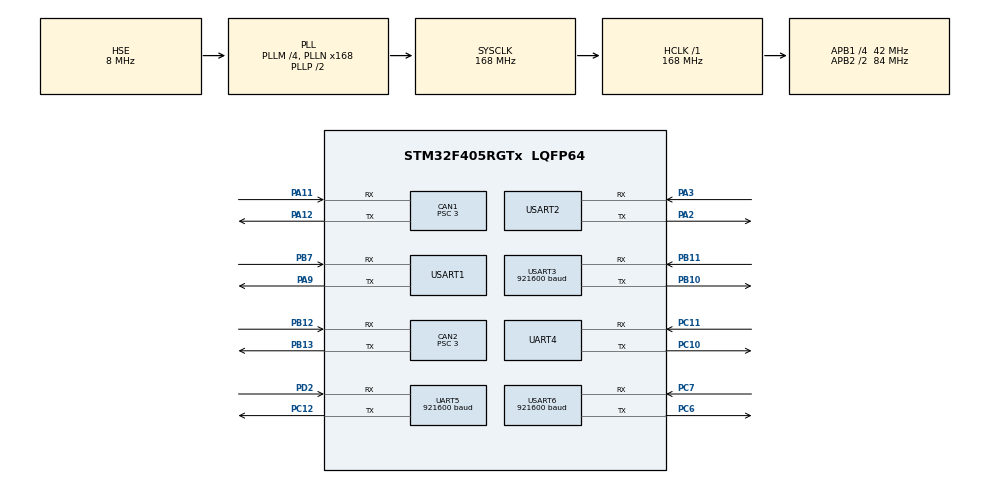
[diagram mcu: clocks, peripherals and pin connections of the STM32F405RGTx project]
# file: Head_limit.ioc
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CAN1.ABOM=ENABLE
CAN1.BS1=CAN_BS1_10TQ
CAN1.BS2=CAN_BS2_3TQ
CAN1.CalculateBaudRate=1000000
CAN1.CalculateTimeBit=1000
CAN1.CalculateTimeQuantum=71.42857142857143
CAN1.NART=ENABLE
CAN1.Prescaler=3
CAN2.ABOM=ENABLE
CAN2.BS1=CAN_BS1_10TQ
CAN2.BS2=CAN_BS2_3TQ
CAN2.CalculateBaudRate=1000000
CAN2.CalculateTimeBit=1000
CAN2.CalculateTimeQuantum=71.42857142857143
CAN2.NART=ENABLE
CAN2.Prescaler=3
Dma.Request0=USART2_RX
Dma.Request1=USART2_TX
Dma.Request2=USART3_RX
Dma.Request3=USART6_RX
Dma.Request4=UART5_RX
Dma.Request5=USART3_TX
Dma.UART5_RX.4.Direction=DMA_PERIPH_TO_MEMORY
Dma.UART5_RX.4.FIFOMode=DMA_FIFOMODE_DISABLE
Dma.UART5_RX.4.Instance=DMA1_Stream0
Dma.UART5_RX.4.MemDataAlignment=DMA_MDATAALIGN_BYTE
Dma.UART5_RX.4.MemInc=DMA_MINC_ENABLE
Dma.UART5_RX.4.Mode=DMA_CIRCULAR
Dma.UART5_RX.4.PeriphDataAlignment=DMA_PDATAALIGN_BYTE
Dma.UART5_RX.4.PeriphInc=DMA_PINC_DISABLE
Dma.UART5_RX.4.Priority=DMA_PRIORITY_LOW
Dma.USART2_RX.0.Direction=DMA_PERIPH_TO_MEMORY
Dma.USART2_RX.0.FIFOMode=DMA_FIFOMODE_DISABLE
Dma.USART2_RX.0.Instance=DMA1_Stream5
Dma.USART2_RX.0.MemDataAlignment=DMA_MDATAALIGN_BYTE
Dma.USART2_RX.0.MemInc=DMA_MINC_ENABLE
Dma.USART2_RX.0.Mode=DMA_CIRCULAR
Dma.USART2_RX.0.PeriphDataAlignment=DMA_PDATAALIGN_BYTE
Dma.USART2_RX.0.PeriphInc=DMA_PINC_DISABLE
Dma.USART2_RX.0.Priority=DMA_PRIORITY_LOW
Dma.USART2_TX.1.Direction=DMA_MEMORY_TO_PERIPH
Dma.USART2_TX.1.FIFOMode=DMA_FIFOMODE_DISABLE
Dma.USART2_TX.1.Instance=DMA1_Stream6
Dma.USART2_TX.1.MemDataAlignment=DMA_MDATAALIGN_BYTE
Dma.USART2_TX.1.MemInc=DMA_MINC_ENABLE
Dma.USART2_TX.1.Mode=DMA_CIRCULAR
Dma.USART2_TX.1.PeriphDataAlignment=DMA_PDATAALIGN_BYTE
Dma.USART2_TX.1.PeriphInc=DMA_PINC_DISABLE
Dma.USART2_TX.1.Priority=DMA_PRIORITY_LOW
Dma.USART3_RX.2.Direction=DMA_PERIPH_TO_MEMORY
Dma.USART3_RX.2.FIFOMode=DMA_FIFOMODE_DISABLE
Dma.USART3_RX.2.Instance=DMA1_Stream1
Dma.USART3_RX.2.MemDataAlignment=DMA_MDATAALIGN_BYTE
Dma.USART3_RX.2.MemInc=DMA_MINC_ENABLE
Dma.USART3_RX.2.Mode=DMA_CIRCULAR
Dma.USART3_RX.2.PeriphDataAlignment=DMA_PDATAALIGN_BYTE
Dma.USART3_RX.2.PeriphInc=DMA_PINC_DISABLE
Dma.USART3_RX.2.Priority=DMA_PRIORITY_LOW
Dma.USART3_TX.5.Direction=DMA_MEMORY_TO_PERIPH
Dma.USART3_TX.5.FIFOMode=DMA_FIFOMODE_DISABLE
Dma.USART3_TX.5.Instance=DMA1_Stream3
Dma.USART3_TX.5.MemDataAlignment=DMA_MDATAALIGN_BYTE
Dma.USART3_TX.5.MemInc=DMA_MINC_ENABLE
Dma.USART3_TX.5.Mode=DMA_NORMAL
Dma.USART3_TX.5.PeriphDataAlignment=DMA_PDATAALIGN_BYTE
Dma.USART3_TX.5.PeriphInc=DMA_PINC_DISABLE
Dma.USART3_TX.5.Priority=DMA_PRIORITY_LOW
Dma.USART6_RX.3.Direction=DMA_PERIPH_TO_MEMORY
Dma.USART6_RX.3.FIFOMode=DMA_FIFOMODE_DISABLE
Dma.USART6_RX.3.Instance=DMA2_Stream1
Dma.USART6_RX.3.MemDataAlignment=DMA_MDATAALIGN_BYTE
Dma.USART6_RX.3.MemInc=DMA_MINC_ENABLE
Dma.USART6_RX.3.Mode=DMA_CIRCULAR
Dma.USART6_RX.3.PeriphDataAlignment=DMA_PDATAALIGN_BYTE
Dma.USART6_RX.3.PeriphInc=DMA_PINC_DISABLE
Dma.USART6_RX.3.Priority=DMA_PRIORITY_LOW
Mcu.Family=STM32F4
Mcu.Name=STM32F405RGTx
Mcu.Package=LQFP64
NVIC.CAN1_RX0_IRQn=true\:0\:0\:false\:false\:true\:true\:true\:true
NVIC.CAN2_RX0_IRQn=true\:0\:0\:false\:false\:true\:true\:true\:true
NVIC.DMA1_Stream0_IRQn=true\:0\:0\:false\:false\:true\:false\:true\:true
NVIC.DMA1_Stream1_IRQn=true\:0\:0\:false\:false\:true\:false\:true\:true
NVIC.DMA1_Stream3_IRQn=true\:0\:0\:false\:false\:true\:false\:true\:true
NVIC.DMA1_Stream5_IRQn=true\:0\:0\:false\:false\:true\:false\:true\:true
NVIC.DMA1_Stream6_IRQn=true\:0\:0\:false\:false\:true\:false\:true\:true
NVIC.DMA2_Stream1_IRQn=true\:0\:0\:false\:false\:true\:false\:true\:true
NVIC.PriorityGroup=NVIC_PRIORITYGROUP_4
NVIC.TIM6_DAC_IRQn=true\:0\:0\:false\:false\:true\:true\:true\:true
NVIC.UART4_IRQn=true\:0\:0\:false\:false\:true\:true\:true\:true
NVIC.UART5_IRQn=true\:0\:0\:false\:false\:true\:true\:true\:true
NVIC.USART1_IRQn=true\:0\:0\:false\:false\:true\:true\:true\:true
NVIC.USART2_IRQn=true\:0\:0\:false\:false\:true\:true\:true\:true
NVIC.USART3_IRQn=true\:0\:0\:false\:false\:true\:true\:true\:true
NVIC.USART6_IRQn=true\:0\:0\:false\:false\:true\:true\:true\:true
PA11.Mode=CAN_Activate
PA11.Signal=CAN1_RX
PA12.Mode=CAN_Activate
PA12.Signal=CAN1_TX
PA13.Mode=Serial_Wire
PA13.Signal=SYS_JTMS-SWDIO
PA14.Mode=Serial_Wire
PA14.Signal=SYS_JTCK-SWCLK
PA2.Mode=Asynchronous
PA2.Signal=USART2_TX
PA3.GPIO_PuPd=GPIO_NOPULL
PA3.Mode=Asynchronous
PA3.Signal=USART2_RX
PA9.Mode=Asynchronous
PA9.Signal=USART1_TX
PB10.Mode=Asynchronous
PB10.Signal=USART3_TX
PB11.GPIO_PuPd=GPIO_PULLUP
PB11.GPIO_Speed=GPIO_SPEED_FREQ_HIGH
PB11.Mode=Asynchronous
PB11.Signal=USART3_RX
PB12.Mode=CAN_Activate
PB12.Signal=CAN2_RX
PB13.Mode=CAN_Activate
PB13.Signal=CAN2_TX
PB7.Mode=Asynchronous
PB7.Signal=USART1_RX
PC10.Mode=Asynchronous
PC10.Signal=UART4_TX
PC11.Mode=Asynchronous
PC11.Signal=UART4_RX
PC12.Mode=Asynchronous
PC12.Signal=UART5_TX
PC6.GPIO_Speed=GPIO_SPEED_FREQ_HIGH
PC6.Mode=Asynchronous
PC6.Signal=USART6_TX
PC7.Mode=Asynchronous
PC7.Signal=USART6_RX
PD2.Mode=Asynchronous
PD2.Signal=UART5_RX
PH0-OSC_IN.Mode=HSE-External-Oscillator
PH0-OSC_IN.Signal=RCC_OSC_IN
PH1-OSC_OUT.Mode=HSE-External-Oscillator
PH1-OSC_OUT.Signal=RCC_OSC_OUT
ProjectManager.HeapSize=0x200
ProjectManager.StackSize=0x400
ProjectManager.TargetToolchain=MDK-ARM V5.32
RCC.48MHZClocksFreq_Value=84000000
RCC.AHBFreq_Value=168000000
RCC.APB1CLKDivider=RCC_HCLK_DIV4
RCC.APB1Freq_Value=42000000
RCC.APB1TimFreq_Value=84000000
RCC.APB2CLKDivider=RCC_HCLK_DIV2
RCC.APB2Freq_Value=84000000
RCC.APB2TimFreq_Value=168000000
RCC.CortexFreq_Value=168000000
RCC.HCLKFreq_Value=168000000
RCC.HSE_VALUE=8000000
RCC.HSI_VALUE=16000000
RCC.LSE_VALUE=32768
RCC.PLLM=4
RCC.PLLN=168
RCC.PLLSourceVirtual=RCC_PLLSOURCE_HSE
RCC.SYSCLKFreq_VALUE=168000000
RCC.SYSCLKSource=RCC_SYSCLKSOURCE_PLLCLK
RCC.VCOOutputFreq_Value=336000000
TIM6.Period=999
TIM6.Prescaler=83
UART4.VirtualMode=Asynchronous
UART5.BaudRate=921600
UART5.VirtualMode=Asynchronous
USART1.VirtualMode=VM_ASYNC
USART2.VirtualMode=VM_ASYNC
USART3.BaudRate=921600
USART3.VirtualMode=VM_ASYNC
USART6.BaudRate=921600
USART6.VirtualMode=VM_ASYNC
VP_TIM6_VS_ClockSourceINT.Mode=Enable_Timer
board=custom

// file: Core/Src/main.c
/* USER CODE BEGIN Header */
/**
  ******************************************************************************
  * @file           : main.c
  * @brief          : Main program body
  ******************************************************************************
  * @attention
  *
  * Copyright (c) 2026 STMicroelectronics.
  * All rights reserved.
  *
  * This software is licensed under terms that can be found in the LICENSE file
  * in the root directory of this software component.
  * If no LICENSE file comes with this software, it is provided AS-IS.
  *
  ******************************************************************************
  */
/* USER CODE END Header */
#include "main.h"

/* USER CODE BEGIN Includes */
#include "BSP.h"
#include "Shoot_Task.h"
#include "Up_Task.h"

/* USER CODE END Includes */

CAN_HandleTypeDef hcan1;
CAN_HandleTypeDef hcan2;

TIM_HandleTypeDef htim6;

UART_HandleTypeDef huart4;
UART_HandleTypeDef huart5;
UART_HandleTypeDef huart1;
UART_HandleTypeDef huart2;
UART_HandleTypeDef huart3;
UART_HandleTypeDef huart6;
DMA_HandleTypeDef hdma_uart5_rx;
DMA_HandleTypeDef hdma_usart2_rx;
DMA_HandleTypeDef hdma_usart2_tx;
DMA_HandleTypeDef hdma_usart3_rx;
DMA_HandleTypeDef hdma_usart3_tx;
DMA_HandleTypeDef hdma_usart6_rx;

void SystemClock_Config(void);
static void MX_GPIO_Init(void);
static void MX_DMA_Init(void);
static void MX_CAN1_Init(void);
static void MX_CAN2_Init(void);
static void MX_UART4_Init(void);
static void MX_UART5_Init(void);
static void MX_USART1_UART_Init(void);
static void MX_USART2_UART_Init(void);
static void MX_USART3_UART_Init(void);
static void MX_USART6_UART_Init(void);
static void MX_TIM6_Init(void);

int main(void)
{

  /* MCU Configuration--------------------------------------------------------*/

  /* Reset of all peripherals, Initializes the Flash interface and the Systick. */
  HAL_Init();

  /* Configure the system clock */
  SystemClock_Config();

  /* Initialize all configured peripherals */
  MX_GPIO_Init();
  MX_DMA_Init();
  MX_CAN1_Init();
  MX_CAN2_Init();
  MX_UART4_Init();
  MX_UART5_Init();
  MX_USART1_UART_Init();
  MX_USART2_UART_Init();
  MX_USART3_UART_Init();
  MX_USART6_UART_Init();
  MX_TIM6_Init();
  /* USER CODE BEGIN 2 */
  /* 启动 BSP 侧的软件初始化，包括串口 DMA、CAN 和 1 kHz 定时器任务。 */
  BSP_Init();
  /* 初始化控制任务状态。 */
  Up_Task_Init();
  Shoot_Task_Init();

  /* USER CODE END 2 */

  /* Infinite loop */
  while (1)
  {

    /* USER CODE BEGIN 3 */
    /* 主循环持续消费串口环形缓冲，并分发给遥控/IMU 模块解析。 */
    BSP_Poll();
  }
  /* USER CODE END 3 */
}

void SystemClock_Config(void)
{
  RCC_OscInitTypeDef RCC_OscInitStruct = {0};
  RCC_ClkInitTypeDef RCC_ClkInitStruct = {0};

  /** Configure the main internal regulator output voltage
  */
  __HAL_RCC_PWR_CLK_ENABLE();
  __HAL_PWR_VOLTAGESCALING_CONFIG(PWR_REGULATOR_VOLTAGE_SCALE1);

  /** Initializes the RCC Oscillators according to the specified parameters
  * in the RCC_OscInitTypeDef structure.
  */
  RCC_OscInitStruct.OscillatorType = RCC_OSCILLATORTYPE_HSE;
  RCC_OscInitStruct.HSEState = RCC_HSE_ON;
  RCC_OscInitStruct.PLL.PLLState = RCC_PLL_ON;
  RCC_OscInitStruct.PLL.PLLSource = RCC_PLLSOURCE_HSE;
  RCC_OscInitStruct.PLL.PLLM = 4;
  RCC_OscInitStruct.PLL.PLLN = 168;
  RCC_OscInitStruct.PLL.PLLP = RCC_PLLP_DIV2;
  RCC_OscInitStruct.PLL.PLLQ = 4;
  if (HAL_RCC_OscConfig(&RCC_OscInitStruct) != HAL_OK)
  {
    Error_Handler();
  }

  /** Initializes the CPU, AHB and APB buses clocks
  */
  RCC_ClkInitStruct.ClockType = RCC_CLOCKTYPE_HCLK|RCC_CLOCKTYPE_SYSCLK
                              |RCC_CLOCKTYPE_PCLK1|RCC_CLOCKTYPE_PCLK2;
  RCC_ClkInitStruct.SYSCLKSource = RCC_SYSCLKSOURCE_PLLCLK;
  RCC_ClkInitStruct.AHBCLKDivider = RCC_SYSCLK_DIV1;
  RCC_ClkInitStruct.APB1CLKDivider = RCC_HCLK_DIV4;
  RCC_ClkInitStruct.APB2CLKDivider = RCC_HCLK_DIV2;

  if (HAL_RCC_ClockConfig(&RCC_ClkInitStruct, FLASH_LATENCY_5) != HAL_OK)
  {
    Error_Handler();
  }
}

static void MX_CAN1_Init(void)
{

  hcan1.Instance = CAN1;
  hcan1.Init.Prescaler = 3;
  hcan1.Init.Mode = CAN_MODE_NORMAL;
  hcan1.Init.SyncJumpWidth = CAN_SJW_1TQ;
  hcan1.Init.TimeSeg1 = CAN_BS1_10TQ;
  hcan1.Init.TimeSeg2 = CAN_BS2_3TQ;
  hcan1.Init.TimeTriggeredMode = DISABLE;
  hcan1.Init.AutoBusOff = ENABLE;
  hcan1.Init.AutoWakeUp = DISABLE;
  hcan1.Init.AutoRetransmission = ENABLE;
  hcan1.Init.ReceiveFifoLocked = DISABLE;
  hcan1.Init.TransmitFifoPriority = DISABLE;
  if (HAL_CAN_Init(&hcan1) != HAL_OK)
  {
    Error_Handler();
  }

}

static void MX_CAN2_Init(void)
{

  hcan2.Instance = CAN2;
  hcan2.Init.Prescaler = 3;
  hcan2.Init.Mode = CAN_MODE_NORMAL;
  hcan2.Init.SyncJumpWidth = CAN_SJW_1TQ;
  hcan2.Init.TimeSeg1 = CAN_BS1_10TQ;
  hcan2.Init.TimeSeg2 = CAN_BS2_3TQ;
  hcan2.Init.TimeTriggeredMode = DISABLE;
  hcan2.Init.AutoBusOff = ENABLE;
  hcan2.Init.AutoWakeUp = DISABLE;
  hcan2.Init.AutoRetransmission = ENABLE;
  hcan2.Init.ReceiveFifoLocked = DISABLE;
  hcan2.Init.TransmitFifoPriority = DISABLE;
  if (HAL_CAN_Init(&hcan2) != HAL_OK)
  {
    Error_Handler();
  }

}

static void MX_TIM6_Init(void)
{

  TIM_MasterConfigTypeDef sMasterConfig = {0};

  htim6.Instance = TIM6;
  htim6.Init.Prescaler = 83;
  htim6.Init.CounterMode = TIM_COUNTERMODE_UP;
  htim6.Init.Period = 999;
  htim6.Init.AutoReloadPreload = TIM_AUTORELOAD_PRELOAD_DISABLE;
  if (HAL_TIM_Base_Init(&htim6) != HAL_OK)
  {
    Error_Handler();
  }
  sMasterConfig.MasterOutputTrigger = TIM_TRGO_RESET;
  sMasterConfig.MasterSlaveMode = TIM_MASTERSLAVEMODE_DISABLE;
  if (HAL_TIMEx_MasterConfigSynchronization(&htim6, &sMasterConfig) != HAL_OK)
  {
    Error_Handler();
  }

}

static void MX_UART4_Init(void)
{

  huart4.Instance = UART4;
  huart4.Init.BaudRate = 115200;
  huart4.Init.WordLength = UART_WORDLENGTH_8B;
  huart4.Init.StopBits = UART_STOPBITS_1;
  huart4.Init.Parity = UART_PARITY_NONE;
  huart4.Init.Mode = UART_MODE_TX_RX;
  huart4.Init.HwFlowCtl = UART_HWCONTROL_NONE;
  huart4.Init.OverSampling = UART_OVERSAMPLING_16;
  if (HAL_UART_Init(&huart4) != HAL_OK)
  {
    Error_Handler();
  }

}

static void MX_UART5_Init(void)
{

  huart5.Instance = UART5;
  huart5.Init.BaudRate = 921600;
  huart5.Init.WordLength = UART_WORDLENGTH_8B;
  huart5.Init.StopBits = UART_STOPBITS_1;
  huart5.Init.Parity = UART_PARITY_NONE;
  huart5.Init.Mode = UART_MODE_TX_RX;
  huart5.Init.HwFlowCtl = UART_HWCONTROL_NONE;
  huart5.Init.OverSampling = UART_OVERSAMPLING_16;
  if (HAL_UART_Init(&huart5) != HAL_OK)
  {
    Error_Handler();
  }

}

static void MX_USART1_UART_Init(void)
{

  huart1.Instance = USART1;
  huart1.Init.BaudRate = 115200;
  huart1.Init.WordLength = UART_WORDLENGTH_8B;
  huart1.Init.StopBits = UART_STOPBITS_1;
  huart1.Init.Parity = UART_PARITY_NONE;
  huart1.Init.Mode = UART_MODE_TX_RX;
  huart1.Init.HwFlowCtl = UART_HWCONTROL_NONE;
  huart1.Init.OverSampling = UART_OVERSAMPLING_16;
  if (HAL_UART_Init(&huart1) != HAL_OK)
  {
    Error_Handler();
  }

}

static void MX_USART2_UART_Init(void)
{

  huart2.Instance = USART2;
  huart2.Init.BaudRate = 115200;
  huart2.Init.WordLength = UART_WORDLENGTH_8B;
  huart2.Init.StopBits = UART_STOPBITS_1;
  huart2.Init.Parity = UART_PARITY_NONE;
  huart2.Init.Mode = UART_MODE_TX_RX;
  huart2.Init.HwFlowCtl = UART_HWCONTROL_NONE;
  huart2.Init.OverSampling = UART_OVERSAMPLING_16;
  if (HAL_UART_Init(&huart2) != HAL_OK)
  {
    Error_Handler();
  }

}

static void MX_USART3_UART_Init(void)
{

  huart3.Instance = USART3;
  huart3.Init.BaudRate = 921600;
  huart3.Init.WordLength = UART_WORDLENGTH_8B;
  huart3.Init.StopBits = UART_STOPBITS_1;
  huart3.Init.Parity = UART_PARITY_NONE;
  huart3.Init.Mode = UART_MODE_TX_RX;
  huart3.Init.HwFlowCtl = UART_HWCONTROL_NONE;
  huart3.Init.OverSampling = UART_OVERSAMPLING_16;
  if (HAL_UART_Init(&huart3) != HAL_OK)
  {
    Error_Handler();
  }

}

static void MX_USART6_UART_Init(void)
{

  huart6.Instance = USART6;
  huart6.Init.BaudRate = 921600;
  huart6.Init.WordLength = UART_WORDLENGTH_8B;
  huart6.Init.StopBits = UART_STOPBITS_1;
  huart6.Init.Parity = UART_PARITY_NONE;
  huart6.Init.Mode = UART_MODE_TX_RX;
  huart6.Init.HwFlowCtl = UART_HWCONTROL_NONE;
  huart6.Init.OverSampling = UART_OVERSAMPLING_16;
  if (HAL_UART_Init(&huart6) != HAL_OK)
  {
    Error_Handler();
  }

}

static void MX_DMA_Init(void)
{

  /* DMA controller clock enable */
  __HAL_RCC_DMA1_CLK_ENABLE();
  __HAL_RCC_DMA2_CLK_ENABLE();

  /* DMA interrupt init */
  /* DMA1_Stream0_IRQn interrupt configuration */
  HAL_NVIC_SetPriority(DMA1_Stream0_IRQn, 0, 0);
  HAL_NVIC_EnableIRQ(DMA1_Stream0_IRQn);
  /* DMA1_Stream1_IRQn interrupt configuration */
  HAL_NVIC_SetPriority(DMA1_Stream1_IRQn, 0, 0);
  HAL_NVIC_EnableIRQ(DMA1_Stream1_IRQn);
  /* DMA1_Stream3_IRQn interrupt configuration */
  HAL_NVIC_SetPriority(DMA1_Stream3_IRQn, 0, 0);
  HAL_NVIC_EnableIRQ(DMA1_Stream3_IRQn);
  /* DMA1_Stream5_IRQn interrupt configuration */
  HAL_NVIC_SetPriority(DMA1_Stream5_IRQn, 0, 0);
  HAL_NVIC_EnableIRQ(DMA1_Stream5_IRQn);
  /* DMA1_Stream6_IRQn interrupt configuration */
  HAL_NVIC_SetPriority(DMA1_Stream6_IRQn, 0, 0);
  HAL_NVIC_EnableIRQ(DMA1_Stream6_IRQn);
  /* DMA2_Stream1_IRQn interrupt configuration */
  HAL_NVIC_SetPriority(DMA2_Stream1_IRQn, 0, 0);
  HAL_NVIC_EnableIRQ(DMA2_Stream1_IRQn);

}

static void MX_GPIO_Init(void)
{

  /* GPIO Ports Clock Enable */
  __HAL_RCC_GPIOH_CLK_ENABLE();
  __HAL_RCC_GPIOA_CLK_ENABLE();
  __HAL_RCC_GPIOB_CLK_ENABLE();
  __HAL_RCC_GPIOC_CLK_ENABLE();
  __HAL_RCC_GPIOD_CLK_ENABLE();

}

void Error_Handler(void)
{
  __disable_irq();
  while (1)
  {
  }
}
